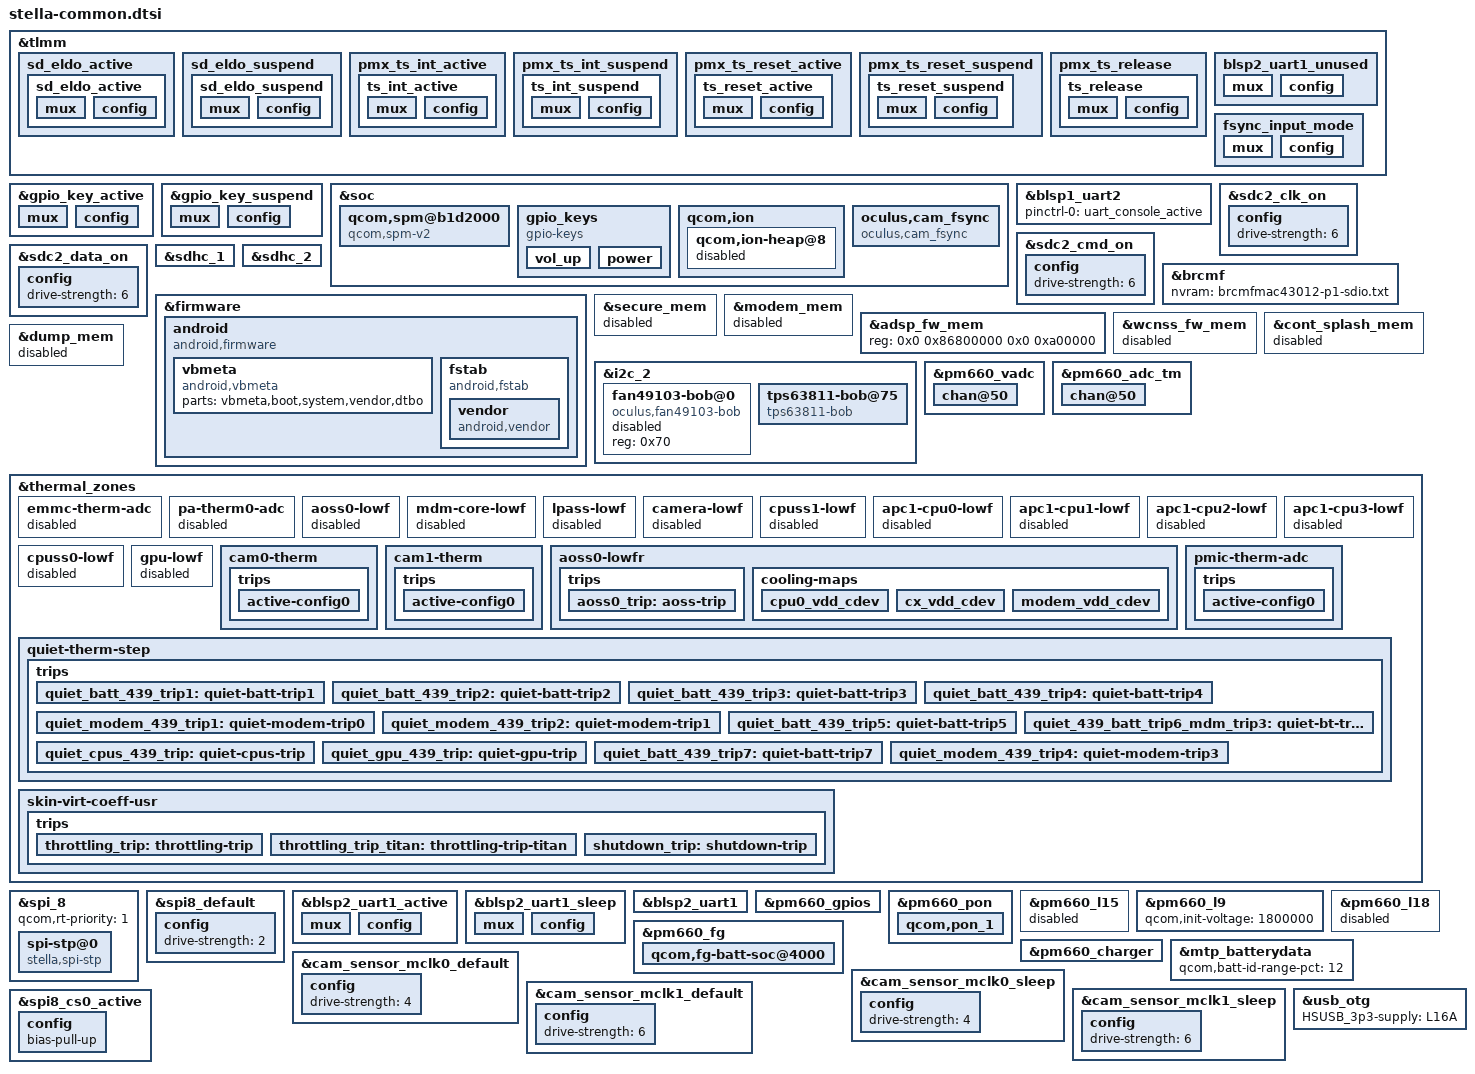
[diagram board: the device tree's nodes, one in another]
/*
 * Copyright (c) 2019, The Linux Foundation. All rights reserved.
 *
 * This program is free software; you can redistribute it and/or modify
 * it under the terms of the GNU General Public License version 2 and
 * only version 2 as published by the Free Software Foundation.
 *
 * This program is distributed in the hope that it will be useful,
 * but WITHOUT ANY WARRANTY; without even the implied warranty of
 * MERCHANTABILITY or FITNESS FOR A PARTICULAR PURPOSE.  See the
 * GNU General Public License for more details.
 */

#include "stella-panels.dtsi"
#include "stella-camera.dtsi"
#include "stella-audio.dtsi"
#include "stella-hw-debug.dtsi"
#include "stella-rt600.dtsi"
#include "stella-cypress-wifi.dtsi"
#include <dt-bindings/interrupt-controller/irq.h>
#include <dt-bindings/thermal/thermal.h>

&tlmm {
	sd_eldo_active {
		sd_eldo_active: sd_eldo_active {
			mux {
				pins = "gpio91";
				function = "gpio";
			};

			config {
				pins = "gpio91";
				drive-strength = <2>;
				bias-pull-up;
			};
		};
	};

	sd_eldo_suspend {
		sd_eldo_suspend: sd_eldo_suspend {
			mux {
				pins = "gpio91";
				function = "gpio";
			};

			config {
				pins = "gpio91";
				drive-strength = <2>;
				bias-disable;
			};
		};
	};
};

&gpio_key_active {
	mux {
		pins = "gpio127", "gpio128", "gpio35", "gpio62", "gpio126";
		function = "gpio";
	};

	config {
		pins = "gpio127", "gpio128", "gpio35", "gpio62", "gpio126";
		drive-strength = <2>;
		bias-pull-up;
	};
};

&gpio_key_suspend {
	mux {
		pins = "gpio127", "gpio128", "gpio35", "gpio62", "gpio126";
		function = "gpio";
	};

	config {
		pins = "gpio127", "gpio128", "gpio35", "gpio62", "gpio126";
		drive-strength = <2>;
		bias-pull-up;
	};
};

&soc {
	/delete-node/ qcom,spm@b1d2000;
	qcom,spm@b1d2000 {
		compatible = "qcom,spm-v2";
		#address-cells = <1>;
		#size-cells = <1>;
		reg = <0xb1d2000 0x1000>;
		qcom,name = "system-cci";
		qcom,saw2-ver-reg = <0xfd0>;
		qcom,saw2-cfg = <0x14>;
		qcom,saw2-spm-dly= <0x3C102800>;
		qcom,saw2-spm-ctl = <0xe>;
		qcom,cpu-vctl-list = <&CPU0 &CPU1 &CPU2 &CPU3>;
		qcom,vctl-timeout-us = <500>;
		qcom,vctl-port = <0x0>;
		qcom,vctl-port-ub = <0x1>;
		qcom,pfm-port = <0x2>;
	};

	gpio_keys: gpio_keys {
		compatible = "gpio-keys";
		label = "gpio-keys";
		pinctrl-names = "default";
		pinctrl-0 = <&gpio_key_active>;
		pinctrl-1 = <&gpio_key_suspend>;

		vol_up: vol_up {
			label = "volume_up";
			gpios = <&tlmm 35 0x1>;
			linux,input-type = <1>;
			linux,code = <115>;
			debounce-interval = <15>;
			linux,can-disable;
			gpio-key,wakeup;
		};

		power: power {
			label = "power";
			gpios = <&tlmm 62 0x1>;
			linux,input-type = <1>;
			linux,code = <116>;
			debounce-interval = <15>;
		};
	};
};

&blsp1_uart2 {
	status = "ok";
	pinctrl-names = "default";
	pinctrl-0 = <&uart_console_active>;
};

&sdc2_clk_on {
  config {
    drive-strength = <6>;
  };
};

&sdc2_cmd_on {
  config {
    drive-strength = <6>;
  };
};

&sdc2_data_on {
  config {
    drive-strength = <6>;
  };
};

&brcmf {
	nvram = "brcmfmac43012-p1-sdio.txt";
};

&sdhc_1 {
	/* device core power supply */
	vdd-supply = <&L19A>;
	qcom,vdd-voltage-level = <2900000 3200000>;
	qcom,vdd-current-level = <200 570000>;

	/* device communication power supply */
	vdd-io-supply = <&L13A>;
	qcom,vdd-io-always-on;
	qcom,vdd-io-lpm-sup;
	qcom,vdd-io-voltage-level = <1800000 1800000>;
	qcom,vdd-io-current-level = <0 60000>;

	pinctrl-names = "active", "sleep";
	pinctrl-0 = <&sdc1_clk_on &sdc1_cmd_on &sdc1_data_on &sdc1_rclk_on>;
	pinctrl-1 = <&sdc1_clk_off &sdc1_cmd_off &sdc1_data_off &sdc1_rclk_off>;

	qcom,clk-rates = <400000 20000000 25000000 50000000 100000000 192000000
								384000000>;
	qcom,nonremovable;
	qcom,bus-speed-mode = "HS400_1p8v", "HS200_1p8v", "DDR_1p8v";

	status = "ok";
};

&sdhc_2 {
	/* device core power supply for sd card*/
	vdd-supply = <&vreg_sd_vdd>;
	qcom,vdd-voltage-level = <2950000 2950000>;
	qcom,vdd-current-level = <15000 800000>;

	/* device communication power supply for msm_io*/
	vdd-io-supply = <&vreg_sd_pad>;
	qcom,vdd-io-voltage-level = <1800000 2950000>;
	qcom,vdd-io-current-level = <200 22000>;

	pinctrl-names = "active", "sleep";
	pinctrl-0 = <&sdc2_clk_on &sdc2_cmd_on &sdc2_data_on
							&sd_eldo_active>;
	pinctrl-1 = <&sdc2_clk_off &sdc2_cmd_off &sdc2_data_off
							&sd_eldo_suspend>;
	qcom,clk-rates = <400000 20000000 25000000 50000000 100000000
								200000000>;

	qcom,bus-speed-mode = "SDR12", "SDR25", "SDR50", "DDR50", "SDR104";

	status = "ok";
};

&firmware {
	android {
		compatible = "android,firmware";
		vbmeta {
			compatible = "android,vbmeta";
			parts = "vbmeta,boot,system,vendor,dtbo";
		};
		fstab {
			compatible = "android,fstab";
			vendor {
				compatible = "android,vendor";
				dev =
		"/dev/block/platform/soc/7824900.sdhci/by-name/vendor";
				type = "ext4";
				mnt_flags = "ro,barrier=1,discard";
				fsmgr_flags = "wait,slotselect,avb";
				status = "ok";
			};
		};
	};
};

&soc {
	qcom,ion {
		qcom,ion-heap@8 { /* CP_MM HEAP */
			status = "disabled";
		};
	};
};

&secure_mem {
	status = "disabled";
};

&modem_mem {
	status = "disabled";
};

&adsp_fw_mem {
	reg = <0x0 0x86800000 0x0 0xa00000>;
};

&wcnss_fw_mem {
	status = "disabled";
};

&cont_splash_mem {
	status = "disabled";
};

&dump_mem {
	status = "disabled";
};

&i2c_2 {
	status = "ok";

	fan49103-bob@0 {
		status = "disabled";
		compatible = "oculus,fan49103-bob";
		/*
		 * NOTE: datasheet shows 0xE0 as address, but need to right shift
		 *       by one to satisfy 7-bit requirement
		 */
		reg = <0x70>;
	};

	tps63811-bob@75 {
		compatible = "tps63811-bob";
		on-gpio  = <&pm660_gpios 13 0>;
		vout_mv = <3400>;
		rf-supply = <&pm660_l9>;
		reg = <0x75>;
	};
};

&tlmm {
	pmx_ts_int_active {
		ts_int_active: ts_int_active {
			mux {
				pins = "gpio65";
				function = "gpio";
			};

			config {
				pins = "gpio65";
				drive-strength = <8>;
				bias-pull-up;
			};
		};
	};

	pmx_ts_int_suspend {
		ts_int_suspend: ts_int_suspend {
			mux {
				pins = "gpio65";
				function = "gpio";
			};

			config {
				pins = "gpio65";
				drive-strength = <2>;
				bias-pull-down;
			};
		};
	};

	pmx_ts_reset_active {
		ts_reset_active: ts_reset_active {
			mux {
				pins = "gpio64";
				function = "gpio";
			};

			config {
				pins = "gpio64";
				drive-strength = <8>;
				bias-pull-up;
			};
		};
	};

	pmx_ts_reset_suspend {
		ts_reset_suspend: ts_reset_suspend {
			mux {
				pins = "gpio64";
				function = "gpio";
			};

			config {
				pins = "gpio64";
				drive-strength = <2>;
				bias-pull-down;
			};
		};
	};

	pmx_ts_release {
		ts_release: ts_release {
			mux {
				pins = "gpio65", "gpio64";
				function = "gpio";
			};

			config {
				pins = "gpio65", "gpio64";
				drive-strength = <2>;
				bias-pull-down;
			};
		};
	};

};

&pm660_vadc {
	chan@50 {
		label = "pmic_therm";
		reg = <0x50>;
		qcom,decimation = <2>;
		qcom,pre-div-channel-scaling = <0>;
		qcom,calibration-type = "ratiometric";
		qcom,scale-function = <2>;
		qcom,hw-settle-time = <2>;
		qcom,fast-avg-setup = <0>;
	};
};

&pm660_adc_tm {
	chan@50 {
		label = "pmic_therm";
		reg = <0x50>;
		qcom,pre-div-channel-scaling = <0>;
		qcom,calibration-type = "ratiometric";
		qcom,scale-function = <2>;
		qcom,hw-settle-time = <2>;
		qcom,btm-channel-number = <0x48>;
		qcom,thermal-node;
	};
};

&thermal_zones {

	emmc-therm-adc {
		status = "disabled";
	};

	pa-therm0-adc {
		status = "disabled";
	};

	aoss0-lowf {
		status = "disabled";
	};

	mdm-core-lowf {
		status = "disabled";
	};

	lpass-lowf {
		status = "disabled";
	};

	camera-lowf {
		status = "disabled";
	};

	cpuss1-lowf {
		status = "disabled";
	};

	apc1-cpu0-lowf {
		status = "disabled";
	};

	apc1-cpu1-lowf {
		status = "disabled";
	};

	apc1-cpu2-lowf {
		status = "disabled";
	};

	apc1-cpu3-lowf {
		status = "disabled";
	};

	cpuss0-lowf {
		status = "disabled";
	};

	gpu-lowf {
		status = "disabled";
	};

	cam0-therm {
		polling-delay-passive = <0>;
		polling-delay = <0>;
		thermal-sensors = <&pm660_adc_tm 0x4e>;
		wake-capable-sensor;
		thermal-governor = "user_space";

		trips {
			active-config0 {
				temperature = <65000>;
				hysteresis = <1000>;
				type = "passive";
			};
		};
	};

	cam1-therm {
		polling-delay-passive = <0>;
		polling-delay = <0>;
		thermal-sensors = <&pm660_adc_tm 0x4f>;
		wake-capable-sensor;
		thermal-governor = "user_space";

		trips {
			active-config0 {
				temperature = <65000>;
				hysteresis = <1000>;
				type = "passive";
			};
		};
	};

	aoss0-lowfr {
		polling-delay-passive = <0>;
		polling-delay = <0>;
		thermal-governor = "low_limits_floor";
		thermal-sensors = <&tsens0 0>;
		tracks-low;

		trips {
			aoss0_trip: aoss-trip {
				temperature = <5000>;
				hysteresis = <5000>;
				type = "passive";
			};
		};

		cooling-maps {
			cpu0_vdd_cdev {
				trip = <&aoss0_trip>;
				cooling-device = <&CPU0 (THERMAL_MAX_LIMIT-2)
						(THERMAL_MAX_LIMIT-2)>;
			};

			cx_vdd_cdev {
				trip = <&aoss0_trip>;
				cooling-device = <&pm660_cx_cdev 0 0>;
			};

			modem_vdd_cdev {
				trip = <&aoss0_trip>;
				cooling-device = <&modem_vdd 0 0>;
			};
		};
	};

	pmic-therm-adc {
		polling-delay-passive = <0>;
		polling-delay = <0>;
		thermal-sensors = <&pm660_adc_tm 0x50>;
		wake-capable-sensor;
		thermal-governor = "user_space";

		trips {
			active-config0 {
				temperature = <65000>;
				hysteresis = <1000>;
				type = "passive";
			};
		};
	};

	quiet-therm-step {
		polling-delay-passive = <1000>;
		polling-delay = <0>;
		thermal-sensors = <&pm660_adc_tm 0x51>;
		thermal-governor = "step_wise";

		trips {
			quiet_batt_439_trip1: quiet-batt-trip1 {
				temperature = <38000>;
				hysteresis = <2000>;
				type = "passive";
			};

			quiet_batt_439_trip2: quiet-batt-trip2 {
				temperature = <40000>;
				hysteresis = <2000>;
				type = "passive";
			};

			quiet_batt_439_trip3: quiet-batt-trip3 {
				temperature = <42000>;
				hysteresis = <2000>;
				type = "passive";
			};

			quiet_batt_439_trip4: quiet-batt-trip4 {
				temperature = <44000>;
				hysteresis = <2000>;
				type = "passive";
			};

			quiet_modem_439_trip1: quiet-modem-trip0 {
				temperature = <44000>;
				hysteresis = <4000>;
				type = "passive";
			};

			quiet_modem_439_trip2: quiet-modem-trip1 {
				temperature = <46000>;
				hysteresis = <4000>;
				type = "passive";
			};

			quiet_batt_439_trip5: quiet-batt-trip5 {
				temperature = <46000>;
				hysteresis = <2000>;
				type = "passive";
			};

			quiet_439_batt_trip6_mdm_trip3: quiet-bt-trp6-mdm-trp3 {
				temperature = <48000>;
				hysteresis = <2000>;
				type = "passive";
			};

			quiet_cpus_439_trip: quiet-cpus-trip {
				temperature = <48000>;
				hysteresis = <0>;
				type = "passive";
			};

			quiet_gpu_439_trip: quiet-gpu-trip {
				temperature = <50000>;
				hysteresis = <0>;
				type = "passive";
			};

			quiet_batt_439_trip7: quiet-batt-trip7 {
				temperature = <50000>;
				hysteresis = <2000>;
				type = "passive";
			};

			quiet_modem_439_trip4: quiet-modem-trip3 {
				temperature = <55000>;
				hysteresis = <5000>;
				type = "passive";
			};
		};
	};

	skin-virt-coeff-usr {
		polling-delay-passive = <0>;
		polling-delay = <2000>;
		thermal-governor = "user_space";

		trips {
			throttling_trip: throttling-trip {
				temperature = <48000>;
				hysteresis = <2000>;
				type = "passive";
			};

			throttling_trip_titan: throttling-trip-titan {
				temperature = <53000>;
				hysteresis = <2000>;
				type = "passive";
			};

			shutdown_trip: shutdown-trip {
				temperature = <57000>;
				hysteresis = <2000>;
				type = "passive";
			};
		};
	};
};

&spi_8 {
	status = "ok";
	qcom,rt-priority = <1>;
	spi-stp@0 {
		status = "ok";
		compatible= "stella,spi-stp";
		reg = <0>;
		spi-max-frequency = <20000000>;
		mcu-has-data  = <&tlmm 73 0>;
		mcu-ready  = <&tlmm 74 0>;
	};
};

&spi8_default {
	config {
		drive-strength = <2>; /* 2 MA */
	};
};

&blsp2_uart1_active {
	mux {
		pins = "gpio16", "gpio17";
		function = "blsp_uart5";
	};

	config {
		pins = "gpio16", "gpio17";
		drive-strength = <2>;
		bias-disable;
	};
};

&blsp2_uart1_sleep {
	mux {
		pins = "gpio16", "gpio17";
		function = "gpio";
	};

	config {
		pins = "gpio16", "gpio17";
		drive-strength = <2>;
		bias-disable;
	};
};

&tlmm {
	blsp2_uart1_unused: blsp2_uart1_unused {
		mux {
			pins = "gpio18", "gpio19";
			function = "gpio";
		};

		config {
			pins = "gpio18", "gpio19";
			drive-strength = <2>;
			bias-pull-down;
		};
	};
};

&blsp2_uart1 {
	status = "ok";
	/* disable RX wake interrupts */
	interrupt-names = "core_irq", "bam_irq";
	interrupts = <0 1>;
	interrupt-map = <0 &intc 0 306 0
			1 &intc 0 239 0>;
	pinctrl-0 = <&blsp2_uart1_sleep &blsp2_uart1_unused>;
	pinctrl-1 = <&blsp2_uart1_active &blsp2_uart1_unused>;
};

/* PMIC_USB_SWITC_EN_N, VREG_BOB_EN, AP_TO_RT600_RST_N */
&pm660_gpios {
	interrupts = <0x0 0xc0 0 IRQ_TYPE_NONE>,
			<0x0 0xc2 0 IRQ_TYPE_NONE>,
			<0x0 0xc7 0 IRQ_TYPE_NONE>,
			<0x0 0xcc 0 IRQ_TYPE_NONE>;
	interrupt-names = "pm660_gpio1", "pm660_gpio3",
			"pm660_gpio8", "pm660_gpio13";
	qcom,gpios-disallowed = <2 4 5 6 7 9 10 11 12>;
};

&pm660_pon {
	/* Reset after pressing power for ~12.2 seconds */
	qcom,pon_1 {
		qcom,support-reset = <1>;
		linux,code = <0>;
		qcom,s1-timer = <10256>;
		qcom,s2-timer = <2000>;
		qcom,s2-type = <7>;
	};
};

&pm660_l15 {
	status = "disabled";
};

&pm660_l9 {
	qcom,init-voltage = <1800000>;
};

&pm660_l18 {
	status = "disabled";
};

&pm660_fg {
	qcom,fg-cutoff-voltage = <3600>;
	qcom,fg-empty-voltage = <3300>;
	qcom,fg-jeita-hyst-temp = <1>;
	qcom,fg-recharge-soc-thr = <96>;
	qcom,fg-sys-term-current = <(-50)>;
	qcom,fg-chg-term-current = <21>;
	qcom,fg-jeita-thresholds = <0 20 45 45>;
	qcom,fg-msoc-low-thr = <10>;
	qcom,suspend-charging-cap-thr = <95>;
	qcom,suspend-charging-temp-thr = <550>;

	qcom,fg-batt-soc@4000 {
		status = "okay";
		reg = <0x4000 0x100>;
		interrupts = <0x0 0x40 0x0 IRQ_TYPE_EDGE_BOTH>,
				<0x0 0x40 0x1 IRQ_TYPE_EDGE_BOTH>,
				<0x0 0x40 0x3 IRQ_TYPE_EDGE_RISING>,
				<0x0 0x40 0x4 IRQ_TYPE_EDGE_BOTH>,
				<0x0 0x40 0x5 IRQ_TYPE_EDGE_RISING>,
				<0x0 0x40 0x7 IRQ_TYPE_EDGE_BOTH>;
		interrupt-names = "soc-update",
				"soc-ready",
				"msoc-delta",
				"msoc-low",
				"msoc-empty",
				"msoc-full";
	};
};

&pm660_charger {
	qcom,sw-jeita-enable;
	qcom,battery-data = <&mtp_batterydata>;
	oculus,usb-icl-val = <500000>;
};

&mtp_batterydata {
	qcom,batt-id-range-pct = <12>;
	#include "fg-gen3-batterydata-pwm3100-167mah.dtsi"
};

&tlmm {
	fsync_input_mode: fsync_input_mode {
		mux {
			pins = "gpio50";
			function = "gpio";
		};

		config {
			pins = "gpio50";
			drive-strength = <2>;
			bias-pull-down;
			input-enable;
		};
	};
};

&soc {
	oculus,cam_fsync {
		compatible = "oculus,cam_fsync";
		delayed-intr-config;
		pinctrl-names = "input";
		pinctrl-0 = <&fsync_input_mode>;
		fsync-gpio  = <&tlmm 50 0>;
		status = "ok";
	};
};

&cam_sensor_mclk0_default {
	config {
		drive-strength = <4>;
	};
};

&cam_sensor_mclk0_sleep {
	config {
		drive-strength = <4>;
	};
};

&cam_sensor_mclk1_default {
	config {
		drive-strength = <6>;
	};
};

&cam_sensor_mclk1_sleep {
	config {
		drive-strength = <6>;
	};
};

&usb_otg {
	HSUSB_3p3-supply = <&L16A>;
};

/* gpio98 */
&spi8_cs0_active {
	config {
		bias-pull-up;
	};
};
